# PIC32MK0128MCA032 register map
Vendor: Microchip
Registers are 32-bit, read-write, reset 0x0 unless marked. A register's access mark holds for its fields unless they carry their own. Addresses are absolute, and some are shared; only a register's first bit layout is shown; [hi:lo] are bit positions; {n}, {i} and the like mark numbered series; 'fields as' and 'values as' point back to an identical list.

## qei
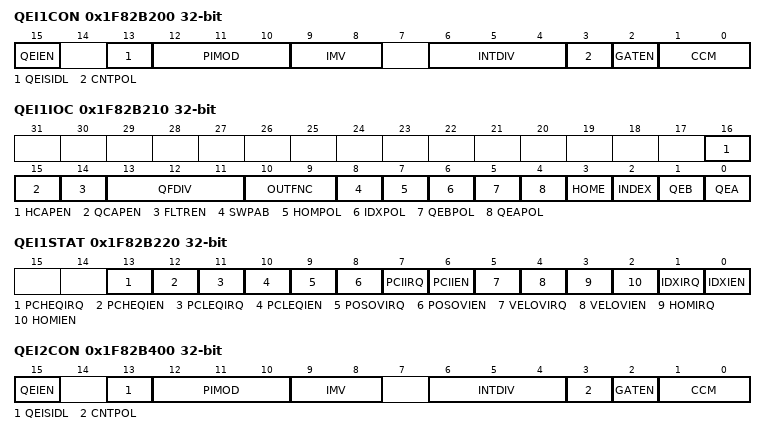
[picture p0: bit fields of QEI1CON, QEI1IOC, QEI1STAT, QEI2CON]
0x1F82B200 QEI1CON
  [15] QEIEN, [13] QEISIDL, [12:10] PIMOD, [9:8] IMV, [6:4] INTDIV, [3] CNTPOL, [2] GATEN, [1:0] CCM
0x1F82B210 QEI1IOC reset not defined — (power-on value ---------------0000000000000xxxx)
  [16] HCAPEN, [15] QCAPEN, [14] FLTREN, [13:11] QFDIV, [10:9] OUTFNC, [8] SWPAB, [7] HOMPOL, [6] IDXPOL, [5] QEBPOL, [4] QEAPOL, [3] HOME ro, [2] INDEX ro, [1] QEB ro, [0] QEA ro
0x1F82B220 QEI1STAT
  [13] PCHEQIRQ, [12] PCHEQIEN, [11] PCLEQIRQ, [10] PCLEQIEN, [9] POSOVIRQ, [8] POSOVIEN, [7] PCIIRQ, [6] PCIIEN, [5] VELOVIRQ, [4] VELOVIEN, [3] HOMIRQ, [2] HOMIEN, [1] IDXIRQ, [0] IDXIEN
0x1F82B230 POS1CNT
  [31:0] POSCNT
0x1F82B240 POS1HLD
  [31:0] POSHLD
0x1F82B250 VEL1CNT
  [31:0] VELCNT
0x1F82B260 VEL1HLD
  [31:0] VELHLD
0x1F82B270 INT1TMR
  [31:0] INTTMR
0x1F82B280 INT1HLD
  [31:0] INTHLD
0x1F82B290 INDX1CNT
  [31:0] INDXCNT
0x1F82B2A0 INDX1HLD
  [31:0] INDXHLD
0x1F82B2B0 QEI1ICC
  [31:0] QEIICC
0x1F82B2C0 QEI1CMPL
  [31:0] QEICMPL
0x1F82B400 QEI2CON
  fields as QEI1CON
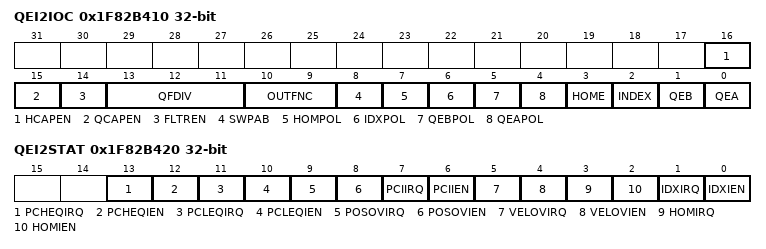
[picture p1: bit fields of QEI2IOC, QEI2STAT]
0x1F82B410 QEI2IOC reset not defined — (power-on value ---------------0000000000000xxxx)
  fields as QEI1IOC
0x1F82B420 QEI2STAT
  fields as QEI1STAT
0x1F82B430 POS2CNT
  [31:0] POSCNT
0x1F82B440 POS2HLD
  [31:0] POSHLD
0x1F82B450 VEL2CNT
  [31:0] VELCNT
0x1F82B460 VEL2HLD
  [31:0] VELHLD
0x1F82B470 INT2TMR
  [31:0] INTTMR
0x1F82B480 INT2HLD
  [31:0] INTHLD
0x1F82B490 INDX2CNT
  [31:0] INDXCNT
0x1F82B4A0 INDX2HLD
  [31:0] INDXHLD
0x1F82B4B0 QEI2ICC
  [31:0] QEIICC
0x1F82B4C0 QEI2CMPL
  [31:0] QEICMPL

## cmp_control_upb
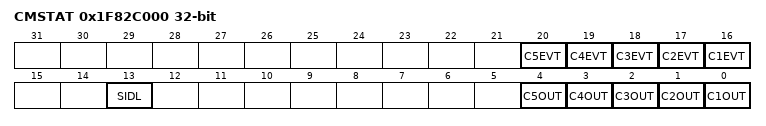
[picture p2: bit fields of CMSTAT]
0x1F82C000 CMSTAT
  [n+15] C{n}EVT ro (n=1..5), [13] SIDL, [n-1] C{n}OUT ro (n=1..5)

## CMP1
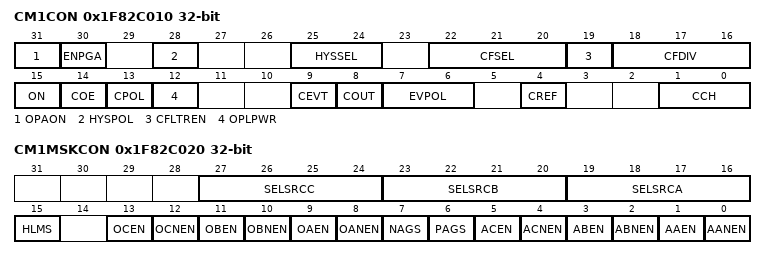
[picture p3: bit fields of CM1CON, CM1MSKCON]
0x1F82C010 CM1CON reset not defined — (power-on value xx-x--00-00000000000--0000-0--00)
  [31] OPAON — Opamp Enable Bit
    1=Opamp Enabled and Connected to Pin; 0=Opamp is disabled and pin is released to other functions
  [30] ENPGA — Opamp Fixed Gain Enable bit
    1=Op amp is operating in Fixed Gain 1X mode; 0=Op amp is operating in Open Loop Mode
  [28] HYSPOL — Comparator Hysteresis Polarity Selection
    1=Hysteresis on falling edge, rising edge is accurate; 0=Hysteresis on rising edge, falling edge is accurate
  [25:24] HYSSEL
  [22:20] CFSEL
  [19] CFLTREN
  [18:16] CFDIV
  [15] ON
  [14] COE
  [13] CPOL
  [12] OPLPWR
  [9] CEVT
  [8] COUT ro
  [7:6] EVPOL
  [4] CREF
  [1:0] CCH
0x1F82C020 CM1MSKCON
  [27:24] SELSRCC, [23:20] SELSRCB, [19:16] SELSRCA, [15] HLMS, [13] OCEN, [12] OCNEN, [11] OBEN, [10] OBNEN, [9] OAEN, [8] OANEN, [7] NAGS, [6] PAGS, [5] ACEN, [4] ACNEN, [3] ABEN, [2] ABNEN, [1] AAEN, [0] AANEN

## CMP2
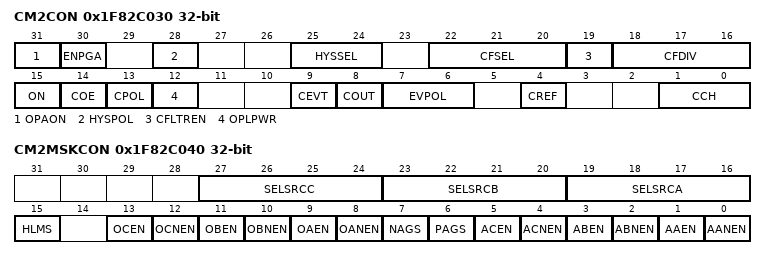
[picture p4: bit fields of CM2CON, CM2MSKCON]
0x1F82C030 CM2CON reset not defined — (power-on value xx-x--00-00000000000--0000-0--00)
  [31] OPAON — Opamp Enable Bit
    1=Opamp Enabled and Connected to Pin; 0=Opamp is disabled and pin is released to other functions
  [30] ENPGA — Opamp Fixed Gain Enable bit
    1=Op amp is operating in Fixed Gain 1X mode; 0=Op amp is operating in Open Loop Mode
  [28] HYSPOL — Comparator Hysteresis Polarity Selection
    1=Hysteresis on falling edge, rising edge is accurate; 0=Hysteresis on rising edge, falling edge is accurate
  [25:24] HYSSEL
  [22:20] CFSEL
  [19] CFLTREN
  [18:16] CFDIV
  [15] ON
  [14] COE
  [13] CPOL
  [12] OPLPWR
  [9] CEVT
  [8] COUT ro
  [7:6] EVPOL
  [4] CREF
  [1:0] CCH
0x1F82C040 CM2MSKCON
  [27:24] SELSRCC, [23:20] SELSRCB, [19:16] SELSRCA, [15] HLMS, [13] OCEN, [12] OCNEN, [11] OBEN, [10] OBNEN, [9] OAEN, [8] OANEN, [7] NAGS, [6] PAGS, [5] ACEN, [4] ACNEN, [3] ABEN, [2] ABNEN, [1] AAEN, [0] AANEN

## CMP3
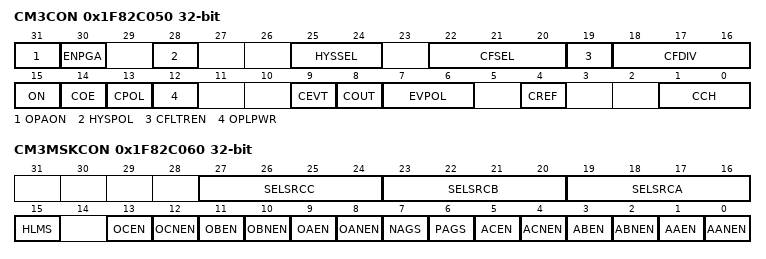
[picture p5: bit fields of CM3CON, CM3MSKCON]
0x1F82C050 CM3CON reset not defined — (power-on value xx-x--00-00000000000--0000-0--00)
  [31] OPAON — Opamp Enable Bit
    1=Opamp Enabled and Connected to Pin; 0=Opamp is disabled and pin is released to other functions
  [30] ENPGA — Opamp Fixed Gain Enable bit
    1=Op amp is operating in Fixed Gain 1X mode; 0=Op amp is operating in Open Loop Mode
  [28] HYSPOL — Comparator Hysteresis Polarity Selection
    1=Hysteresis on falling edge, rising edge is accurate; 0=Hysteresis on rising edge, falling edge is accurate
  [25:24] HYSSEL
  [22:20] CFSEL
  [19] CFLTREN
  [18:16] CFDIV
  [15] ON
  [14] COE
  [13] CPOL
  [12] OPLPWR
  [9] CEVT
  [8] COUT ro
  [7:6] EVPOL
  [4] CREF
  [1:0] CCH
0x1F82C060 CM3MSKCON
  [27:24] SELSRCC, [23:20] SELSRCB, [19:16] SELSRCA, [15] HLMS, [13] OCEN, [12] OCNEN, [11] OBEN, [10] OBNEN, [9] OAEN, [8] OANEN, [7] NAGS, [6] PAGS, [5] ACEN, [4] ACNEN, [3] ABEN, [2] ABNEN, [1] AAEN, [0] AANEN
